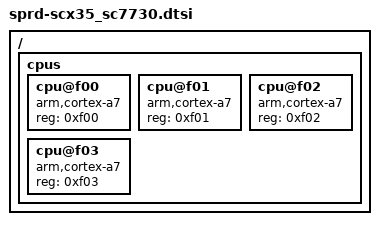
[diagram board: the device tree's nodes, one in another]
/*
 * Copyright (C) 2013 Spreadtrum Communication Incorporated
 *		http://www.spreadtrum.com/
 *
 * This program is free software; you can redistribute it and/or modify
 * it under the terms of the GNU General Public License version 2 as
 * published by the Free Software Foundation.
 */

/ {
	cpus {
		#address-cells = <1>;
		#size-cells = <0>;

		cpu@f00 {
			device_type = "cpu";
			compatible = "arm,cortex-a7";
			reg = <0xf00>;
		};

		cpu@f01 {
			device_type = "cpu";
			compatible = "arm,cortex-a7";
			reg = <0xf01>;
		};

		cpu@f02 {
			device_type = "cpu";
			compatible = "arm,cortex-a7";
			reg = <0xf02>;
		};

		cpu@f03 {
			device_type = "cpu";
			compatible = "arm,cortex-a7";
			reg = <0xf03>;
		};
	};


};

